# GD32A513 register map
File version: 1.0
CPU: CM33 r0p4, little endian, MPU, FPU, 4 interrupt priority bits
Registers are 32-bit, read-write, reset 0x0 unless marked. A register's access mark holds for its fields unless they carry their own. Offsets are from the block's base; [hi:lo] are bit positions.

## RCU — Reset and clock unit
Base 0x40021000
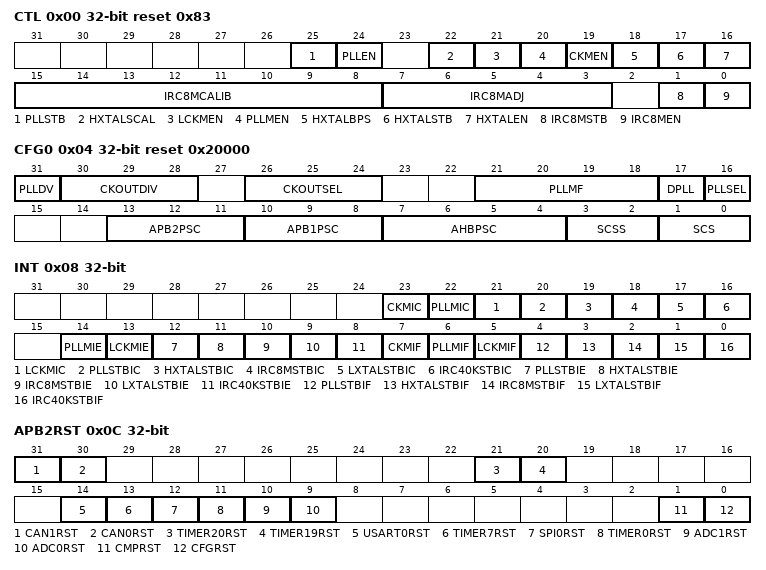
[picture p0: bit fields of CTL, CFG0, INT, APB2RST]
0x00 CTL access per field reset 0x83 — Control register
  [25] PLLSTB ro — PLL Clock Stabilization Flag
  [24] PLLEN rw — PLL enable
  [22] HXTALSCAL rw — HXTAL frequency scale select
  [21] LCKMEN rw — LXTAL clock monitor enable
  [20] PLLMEN rw — PLL clock monitor enable
  [19] CKMEN rw — HXTAL Clock Monitor Enable
  [18] HXTALBPS rw — External crystal oscillator (HXTAL) clock bypass mode enable
  [17] HXTALSTB ro — External crystal oscillator (HXTAL) clock stabilization flag
  [16] HXTALEN rw — External High Speed oscillator Enable
  [15:8] IRC8MCALIB ro — High Speed Internal Oscillator calibration value register
  [7:3] IRC8MADJ rw — High Speed Internal Oscillator clock trim adjust value
  [1] IRC8MSTB ro — IRC8M High Speed Internal Oscillator stabilization Flag
  [0] IRC8MEN rw — Internal High Speed oscillator Enable
0x04 CFG0 access per field reset 0x20000 — Clock configuration register 0 (RCU_CFG0)
  [31] PLLDV rw — The CK_PLL divide by 1 or 2 for CK_OUT
  [30:28] CKOUTDIV rw — The CK_OUT divider which the CK_OUT frequency can be reduced
  [26:24] CKOUTSEL rw — CK_OUT Clock Source Selection
  [21:18] PLLMF rw — PLL multiply factor
  [17] DPLL rw — Double PLL clock.
  [16] PLLSEL rw — PLL Clock Source Selection
  [13:11] APB2PSC rw — APB2 prescaler selection
  [10:8] APB1PSC rw — APB1 prescaler selection
  [7:4] AHBPSC rw — AHB prescaler selection
  [3:2] SCSS ro — System clock switch status
  [1:0] SCS rw — System clock switch
0x08 INT access per field — Clock interrupt register (RCU_INT)
  [23] CKMIC wo — HXTAL Clock Stuck Interrupt Clear
  [22] PLLMIC wo — PLL clock monitor interrupt clear
  [21] LCKMIC wo — LXTAL clock monitor interrupt clear
  [20] PLLSTBIC wo — PLL stabilization Interrupt Clear
  [19] HXTALSTBIC wo — HXTAL Stabilization Interrupt Clear
  [18] IRC8MSTBIC wo — IRC8M Stabilization Interrupt Clear
  [17] LXTALSTBIC wo — LXTAL Stabilization Interrupt Clear
  [16] IRC40KSTBIC wo — IRC40K Stabilization Interrupt Clear
  [14] PLLMIE rw — PLL clock monitor interrupt enable
  [13] LCKMIE rw — LXTAL clock monitor interrupt enable
  [12] PLLSTBIE rw — PLL Stabilization Interrupt Enable
  [11] HXTALSTBIE rw — HXTAL Stabilization Interrupt Enable
  [10] IRC8MSTBIE rw — IRC8M Stabilization Interrupt Enable
  [9] LXTALSTBIE rw — LXTAL Stabilization Interrupt Enable
  [8] IRC40KSTBIE rw — IRC40K Stabilization interrupt enable
  [7] CKMIF ro — HXTAL Clock Stuck Interrupt Flag
  [6] PLLMIF ro — PLL clock monitor interrupt flag
  [5] LCKMIF ro — LXTAL clock monitor interrupt flag
  [4] PLLSTBIF ro — PLL stabilization interrupt flag
  [3] HXTALSTBIF ro — HXTAL stabilization interrupt flag
  [2] IRC8MSTBIF ro — IRC8M stabilization interrupt flag
  [1] LXTALSTBIF ro — LXTAL stabilization interrupt flag
  [0] IRC40KSTBIF ro — IRC40K stabilization interrupt flag
0x0C APB2RST — APB2 reset register (RCU_APB2RST)
  [31] CAN1RST — CAN1 reset
  [30] CAN0RST — CAN0 reset
  [21] TIMER20RST — TIMER20 reset
  [20] TIMER19RST — TIMER19 reset
  [14] USART0RST — USART0 Reset
  [13] TIMER7RST — TIMER7 reset
  [12] SPI0RST — SPI0 Reset
  [11] TIMER0RST — TIMER0 reset
  [10] ADC1RST — ADC1 reset
  [9] ADC0RST — ADC0 reset
  [1] CMPRST — Comparator reset
  [0] CFGRST — System configuration reset
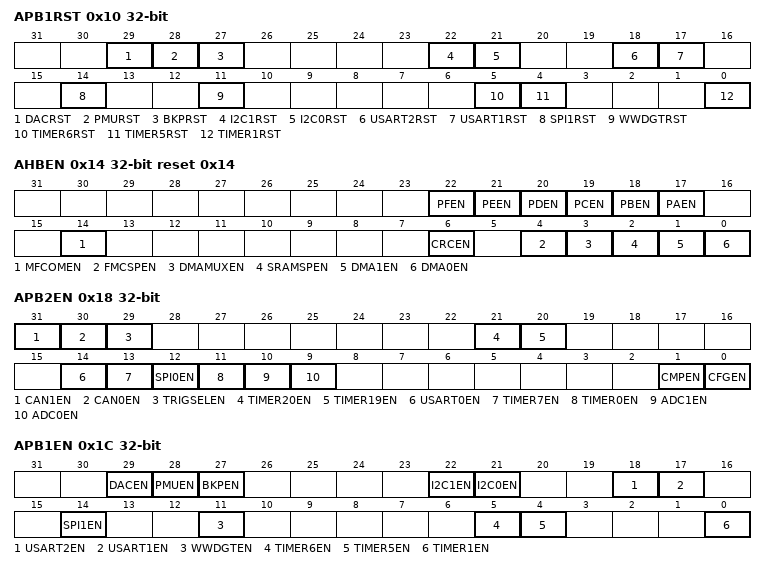
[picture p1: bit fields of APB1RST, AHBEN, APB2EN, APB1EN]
0x10 APB1RST — APB1 reset register (RCU_APB1RST)
  [29] DACRST — DAC reset
  [28] PMURST — Power control reset
  [27] BKPRST — Back-up control reset
  [22] I2C1RST — I2C1 reset
  [21] I2C0RST — I2C0 reset
  [18] USART2RST — USART2 reset
  [17] USART1RST — USART1 reset
  [14] SPI1RST — SPI1 reset
  [11] WWDGTRST — Window watchdog timer reset
  [5] TIMER6RST — TIMER6 timer reset
  [4] TIMER5RST — TIMER5 timer reset
  [0] TIMER1RST — TIMER1 timer reset
0x14 AHBEN reset 0x14 — AHB enable register (RCU_AHBEN)
  [22] PFEN — GPIO port F clock enable
  [21] PEEN — GPIO port E clock enable
  [20] PDEN — GPIO port D clock enable
  [19] PCEN — GPIO port C clock enable
  [18] PBEN — GPIO port B clock enable
  [17] PAEN — GPIO port A clock enable
  [14] MFCOMEN — MFCOM port A clock enable
  [6] CRCEN — CRC clock enable
  [4] FMCSPEN — FMC clock during sleep mode enable
  [3] DMAMUXEN — DMAMUX clock enable
  [2] SRAMSPEN — SRAM interface clock enable
  [1] DMA1EN — DMA1 clock enable
  [0] DMA0EN — DMA0 clock enable
0x18 APB2EN — APB2 enable register (RCU_APB2EN)
  [31] CAN1EN — CAN1 clock enable
  [30] CAN0EN — CAN0 clock enable
  [29] TRIGSELEN — TRIGSEL clock enable
  [21] TIMER20EN — TIMER20 timer clock enable
  [20] TIMER19EN — TIMER19 timer clock enable
  [14] USART0EN — USART0 clock enable
  [13] TIMER7EN — TIMER7 timer clock enable
  [12] SPI0EN — SPI0 clock enable
  [11] TIMER0EN — TIMER0 timer clock enable
  [10] ADC1EN — ADC1 interface clock enable
  [9] ADC0EN — ADC0 interface clock enable
  [1] CMPEN — Comparator clock enable
  [0] CFGEN — System configuration clock enable
0x1C APB1EN — APB1 enable register (RCU_APB1EN)
  [29] DACEN — DAC clock enable
  [28] PMUEN — Power interface clock enable
  [27] BKPEN — Back-up interface clock enable
  [22] I2C1EN — I2C1 clock enable
  [21] I2C0EN — I2C0 clock enable
  [18] USART2EN — USART2 clock enable
  [17] USART1EN — USART1 clock enable
  [14] SPI1EN — SPI1 clock enable
  [11] WWDGTEN — Window watchdog timer clock enable
  [5] TIMER6EN — TIMER6 timer clock enable
  [4] TIMER5EN — TIMER5 timer clock enable
  [0] TIMER1EN — TIMER1 timer clock enable
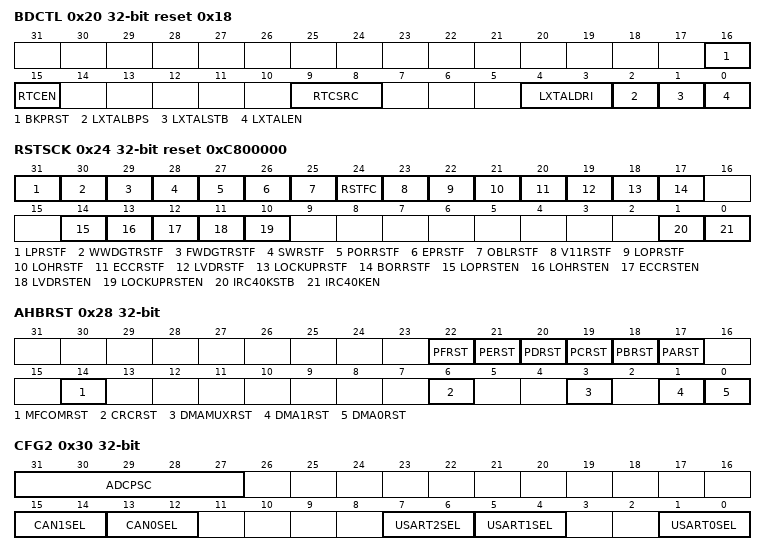
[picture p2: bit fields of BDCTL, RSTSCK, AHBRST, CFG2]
0x20 BDCTL access per field reset 0x18 — Backup domain control register (RCU_BDCTL)
  [16] BKPRST rw — Backup domain reset
  [15] RTCEN rw — RTC clock enable
  [9:8] RTCSRC rw — RTC clock entry selection
  [4:3] LXTALDRI rw — LXTAL drive capability
  [2] LXTALBPS rw — LXTAL bypass mode enable
  [1] LXTALSTB ro — External low-speed oscillator stabilization
  [0] LXTALEN rw — LXTAL enable
0x24 RSTSCK access per field reset 0xC800000 — Reset source /clock register (RCU_RSTSCK)
  [31] LPRSTF rw — Low-power reset flag
  [30] WWDGTRSTF rw — Window watchdog timer reset flag
  [29] FWDGTRSTF rw — Free Watchdog timer reset flag
  [28] SWRSTF rw — Software reset flag
  [27] PORRSTF rw — Power reset flag
  [26] EPRSTF rw — External PIN reset flag
  [25] OBLRSTF rw — Option byte loader reset flag
  [24] RSTFC rw — Reset flag clear
  [23] V11RSTF rw — V11 domain Power reset flag
  [22] LOPRSTF rw — Lost of PLL Error reset flag
  [21] LOHRSTF rw — Lost of HXTAL Error reset flag
  [20] ECCRSTF rw — Two bit ECC Error reset flag
  [19] LVDRSTF ro — Low Voltage Detect Error reset flag
  [18] LOCKUPRSTF ro — CPU LOCK UP Error reset flag
  [17] BORRSTF ro — BOR reset flag
  [14] LOPRSTEN rw — Lost of PLL reset enable
  [13] LOHRSTEN rw — Lost of HXTAL reset enable
  [12] ECCRSTEN rw — ECC 2 bits error reset enable
  [11] LVDRSTEN rw — Low voltage detection reset enable
  [10] LOCKUPRSTEN rw — CPU Lock-Up reset enable
  [1] IRC40KSTB ro — IRC40K stabilization
  [0] IRC40KEN rw — IRC40K enable
0x28 AHBRST — AHB reset register
  [22] PFRST — GPIO port F reset
  [21] PERST — GPIO port E reset
  [20] PDRST — GPIO port D reset
  [19] PCRST — GPIO port C reset
  [18] PBRST — GPIO port B reset
  [17] PARST — GPIO port A reset
  [14] MFCOMRST — MFCOM reset
  [6] CRCRST — CRC reset
  [3] DMAMUXRST — DMAMUX reset
  [1] DMA1RST — DMA1 reset
  [0] DMA0RST — DMA0 reset
0x2C CFG1 — Configuration register 1
  [3:0] PREDV — CK_HXTAL divider previous PLL
0x30 CFG2 — Configuration register 2
  [31:27] ADCPSC — ADC clock prescaler selection
  [15:14] CAN1SEL — CK_CAN1 clock source selection
  [13:12] CAN0SEL — CK_CAN0 clock source selection
  [7:6] USART2SEL — CK_USART2 clock source selection
  [5:4] USART1SEL — CK_USART1 clock source selection
  [1:0] USART0SEL — CK_USART0 clock source selection
0x100 VKEY wo — Voltage key register
  [31:0] KEY — The key of RCU_DSV register
0x134 DSV reset 0x3 — Deep-sleep mode voltage register
  [1:0] DSLPVS — Deep-sleep mode voltage select
